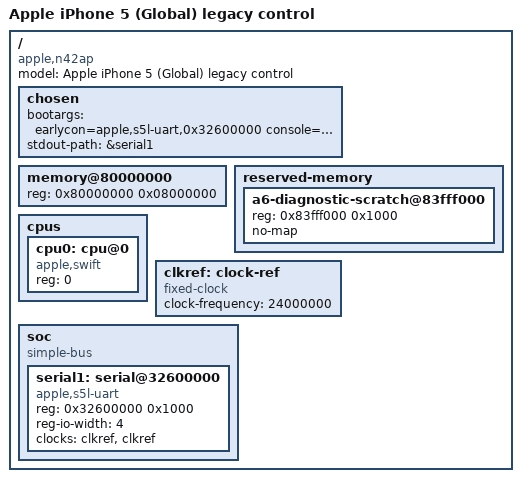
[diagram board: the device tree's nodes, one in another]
/dts-v1/;

/*
 * Historical control profile from before A6 interrupt-controller and timer
 * support was introduced. Keep this deliberately minimal while reproducing
 * the framebuffer-instrumented deep-boot lineage.
 */

/ {
	compatible = "apple,n42ap", "apple,s5l8950x", "apple,arm-platform";
	model = "Apple iPhone 5 (Global) legacy control";
	#address-cells = <1>;
	#size-cells = <1>;

	chosen {
		bootargs = "earlycon=apple,s5l-uart,0x32600000 console=ttySAC0,115200 loglevel=8 panic=0 lpj=1000000";
		stdout-path = &serial1;
	};

	memory@80000000 {
		device_type = "memory";
		reg = <0x80000000 0x08000000>;
	};

	reserved-memory {
		#address-cells = <1>;
		#size-cells = <1>;
		ranges;

		a6-diagnostic-scratch@83fff000 {
			reg = <0x83fff000 0x1000>;
			no-map;
		};

	};

	cpus {
		#address-cells = <1>;
		#size-cells = <0>;

		cpu0: cpu@0 {
			compatible = "apple,swift", "arm,cortex-a9";
			device_type = "cpu";
			reg = <0>;
		};
	};

	clkref: clock-ref {
		compatible = "fixed-clock";
		#clock-cells = <0>;
		clock-frequency = <24000000>;
	};

	soc {
		compatible = "simple-bus";
		#address-cells = <1>;
		#size-cells = <1>;
		ranges;

		serial1: serial@32600000 {
			compatible = "apple,s5l-uart";
			reg = <0x32600000 0x1000>;
			reg-io-width = <4>;
			clocks = <&clkref>, <&clkref>;
			clock-names = "uart", "clk_uart_baud0";
			status = "okay";
		};
	};
};
